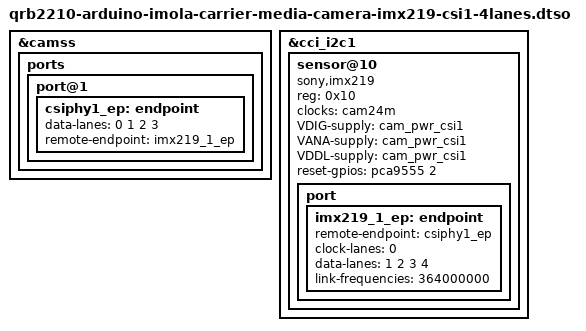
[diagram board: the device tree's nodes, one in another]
// SPDX-License-Identifier: (GPL-2.0+ OR BSD-3-Clause)
/*
 * Copyright (c) 2025, Arduino SA
 */

/dts-v1/;
/plugin/;

#include <dt-bindings/gpio/gpio.h>
#include "qrb2210-arduino-imola-carrier-media-common.dtsi"

&camss {
	ports {
		port@1 {
			csiphy1_ep: endpoint {
				data-lanes = <0 1 2 3>;
				remote-endpoint = <&imx219_1_ep>;
			};
		};
	};
};

&cci_i2c1 {
	#address-cells = <1>;
	#size-cells = <0>;

	sensor@10 {
		compatible = "sony,imx219";
		reg = <0x10>;
		clocks = <&cam24m>;
		status = "okay";

		VDIG-supply = <&cam_pwr_csi1>;
		VANA-supply = <&cam_pwr_csi1>;
		VDDL-supply = <&cam_pwr_csi1>;

		reset-gpios = <&pca9555 2 GPIO_ACTIVE_HIGH>;

		port {
			/* MIPI CSI-2 bus endpoint */
			imx219_1_ep: endpoint {
				remote-endpoint = <&csiphy1_ep>;
				clock-lanes = <0>;
				data-lanes = <1 2 3 4>;
				link-frequencies = /bits/ 64 <364000000>;
			};
		};
	};
};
